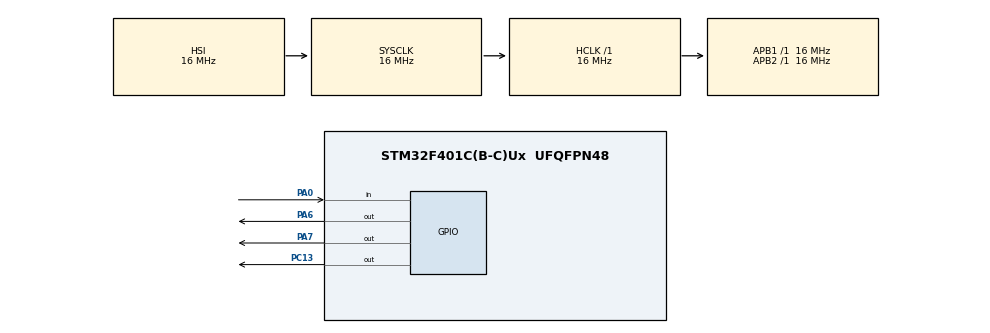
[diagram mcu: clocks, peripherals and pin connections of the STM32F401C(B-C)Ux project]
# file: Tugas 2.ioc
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Mcu.Family=STM32F4
Mcu.Name=STM32F401C(B-C)Ux
Mcu.Package=UFQFPN48
NVIC.PriorityGroup=NVIC_PRIORITYGROUP_4
PA0-WKUP.Signal=GPIO_Input
PA13.Mode=Serial_Wire
PA13.Signal=SYS_JTMS-SWDIO
PA14.Mode=Serial_Wire
PA14.Signal=SYS_JTCK-SWCLK
PA6.Signal=GPIO_Output
PA7.Signal=GPIO_Output
PC13-ANTI_TAMP.Signal=GPIO_Output
ProjectManager.HeapSize=0x200
ProjectManager.StackSize=0x400
ProjectManager.TargetToolchain=STM32CubeIDE
RCC.AHBFreq_Value=16000000
RCC.APB1Freq_Value=16000000
RCC.APB2Freq_Value=16000000
RCC.CortexFreq_Value=16000000
RCC.HSE_VALUE=25000000
RCC.HSI_VALUE=16000000
RCC.LSE_VALUE=32768
RCC.SYSCLKFreq_VALUE=16000000
RCC.VCOOutputFreq_Value=192000000
board=custom

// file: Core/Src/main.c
/* USER CODE BEGIN Header */
/**
  **************************
  * @file           : main.c
  * @brief          : Main program body
  **************************
  * @attention
  *
  * Copyright (c) 2025 STMicroelectronics.
  * All rights reserved.
  *
  * This software is licensed under terms that can be found in the LICENSE file
  * in the root directory of this software component.
  * If no LICENSE file comes with this software, it is provided AS-IS.
  *
  **************************
  */
/* USER CODE END Header */
#include "main.h"

/* USER CODE BEGIN Includes */
volatile uint8_t mode = 4; // Variasi LED (0-3)
volatile uint32_t lastDebounceTimeBtn1 = 0;
volatile uint32_t lastDebounceTimeBtn2 = 0;
const uint32_t debounceDelay = 200; // ms
/* USER CODE END Includes */

/* USER CODE BEGIN PTD */
#define LED_BUILTIN_PIN    GPIO_PIN_13
#define LED_BUILTIN_PORT   GPIOC
#define LED1_PIN           GPIO_PIN_7
#define LED1_PORT          GPIOA
#define LED2_PIN           GPIO_PIN_6
#define LED2_PORT          GPIOA
/* USER CODE END PTD */

/* USER CODE BEGIN PD */
void setLEDsOff(void);
void updateLEDs(uint8_t mode);

/* Callback interrupt tombol dengan debouncing */
void HAL_GPIO_EXTI_Callback(uint16_t GPIO_Pin)
{
    uint32_t currentTime = HAL_GetTick();

    if(GPIO_Pin == GPIO_PIN_0) // Tombol 1: toggle default <-> variasi
    {
        if((currentTime - lastDebounceTimeBtn1) > debounceDelay)
        {
            if(mode == 4)
                mode = 0;
            else
                mode = 4;

            lastDebounceTimeBtn1 = currentTime;
        }
    }
    else if(GPIO_Pin == GPIO_PIN_1) // Tombol 2: loop mode variasi 1-4
    {
        if(((currentTime - lastDebounceTimeBtn2) > debounceDelay ) && (mode != 4))
        {
            mode = (mode + 1) % 3; // 0 -> pola1, 1 -> pola2, 2 -> pola3, 3 -> mati
            lastDebounceTimeBtn2 = currentTime;
        }
    }
}

/* USER CODE END PD */

void SystemClock_Config(void);
static void MX_GPIO_Init(void);

int main(void)
{

  /* MCU Configuration--------------------------------------------------------*/

  /* Reset of all peripherals, Initializes the Flash interface and the Systick. */
  HAL_Init();

  /* Configure the system clock */
  SystemClock_Config();

  /* Initialize all configured peripherals */
  MX_GPIO_Init();

  /* Infinite loop */
  while (1)
  {
	  uint8_t currentMode;
	  __disable_irq();
	  currentMode = mode;
	  __enable_irq();

	  updateLEDs(currentMode);

  }
}

void updateLEDs(uint8_t mode)
{
    switch(mode)
    {

        case 0: // LED PC13 & PB1 kedip bersama 300 ms
            HAL_GPIO_TogglePin(LED_BUILTIN_PORT, LED_BUILTIN_PIN);
            HAL_GPIO_TogglePin(LED1_PORT, LED1_PIN);
            HAL_GPIO_WritePin(LED2_PORT, LED2_PIN, GPIO_PIN_RESET);
            HAL_Delay(300);
            break;

        case 1: // LED PB1 & PB2 nyala bergantian 400 ms
            HAL_GPIO_WritePin(LED_BUILTIN_PORT, LED_BUILTIN_PIN, GPIO_PIN_RESET);
            HAL_GPIO_WritePin(LED1_PORT, LED1_PIN, GPIO_PIN_SET);
            HAL_GPIO_WritePin(LED2_PORT, LED2_PIN, GPIO_PIN_RESET);
            HAL_Delay(400);
            HAL_GPIO_WritePin(LED1_PORT, LED1_PIN, GPIO_PIN_RESET);
            HAL_GPIO_WritePin(LED2_PORT, LED2_PIN, GPIO_PIN_SET);
            HAL_Delay(400);
            break;

        case 2: // Semua LED nyala terus
            HAL_GPIO_WritePin(LED_BUILTIN_PORT, LED_BUILTIN_PIN, GPIO_PIN_SET);
            HAL_GPIO_WritePin(LED1_PORT, LED1_PIN, GPIO_PIN_SET);
            HAL_GPIO_WritePin(LED2_PORT, LED2_PIN, GPIO_PIN_SET);
            HAL_Delay(500);
            break;

        default:
            setLEDsOff();
            HAL_Delay(500);
            break;
    }
}
void SystemClock_Config(void)
{
  RCC_OscInitTypeDef RCC_OscInitStruct = {0};
  RCC_ClkInitTypeDef RCC_ClkInitStruct = {0};

  /** Configure the main internal regulator output voltage
  */
  __HAL_RCC_PWR_CLK_ENABLE();
  __HAL_PWR_VOLTAGESCALING_CONFIG(PWR_REGULATOR_VOLTAGE_SCALE2);

  /** Initializes the RCC Oscillators according to the specified parameters
  * in the RCC_OscInitTypeDef structure.
  */
  RCC_OscInitStruct.OscillatorType = RCC_OSCILLATORTYPE_HSI;
  RCC_OscInitStruct.HSIState = RCC_HSI_ON;
  RCC_OscInitStruct.HSICalibrationValue = RCC_HSICALIBRATION_DEFAULT;
  RCC_OscInitStruct.PLL.PLLState = RCC_PLL_NONE;
  if (HAL_RCC_OscConfig(&RCC_OscInitStruct) != HAL_OK)
  {
    Error_Handler();
  }

  /** Initializes the CPU, AHB and APB buses clocks
  */
  RCC_ClkInitStruct.ClockType = RCC_CLOCKTYPE_HCLK|RCC_CLOCKTYPE_SYSCLK
                              |RCC_CLOCKTYPE_PCLK1|RCC_CLOCKTYPE_PCLK2;
  RCC_ClkInitStruct.SYSCLKSource = RCC_SYSCLKSOURCE_HSI;
  RCC_ClkInitStruct.AHBCLKDivider = RCC_SYSCLK_DIV1;
  RCC_ClkInitStruct.APB1CLKDivider = RCC_HCLK_DIV1;
  RCC_ClkInitStruct.APB2CLKDivider = RCC_HCLK_DIV1;

  if (HAL_RCC_ClockConfig(&RCC_ClkInitStruct, FLASH_LATENCY_0) != HAL_OK)
  {
    Error_Handler();
  }
}

static void MX_GPIO_Init(void)
{
  GPIO_InitTypeDef GPIO_InitStruct = {0};

  /* GPIO Ports Clock Enable */
  __HAL_RCC_GPIOC_CLK_ENABLE();
  __HAL_RCC_GPIOA_CLK_ENABLE();

  /*Configure GPIO pin Output Level */
  HAL_GPIO_WritePin(GPIOC, GPIO_PIN_13, GPIO_PIN_RESET);

  /*Configure GPIO pin Output Level */
  HAL_GPIO_WritePin(GPIOA, GPIO_PIN_6|GPIO_PIN_7, GPIO_PIN_RESET);

  /*Configure GPIO pin : PC13 */
  GPIO_InitStruct.Pin = GPIO_PIN_13;
  GPIO_InitStruct.Mode = GPIO_MODE_OUTPUT_PP;
  GPIO_InitStruct.Pull = GPIO_NOPULL;
  GPIO_InitStruct.Speed = GPIO_SPEED_FREQ_LOW;
  HAL_GPIO_Init(GPIOC, &GPIO_InitStruct);

  /*Configure GPIO pins : PA6 PA7 */
  GPIO_InitStruct.Pin = GPIO_PIN_6|GPIO_PIN_7;
  GPIO_InitStruct.Mode = GPIO_MODE_OUTPUT_PP;
  GPIO_InitStruct.Pull = GPIO_NOPULL;
  GPIO_InitStruct.Speed = GPIO_SPEED_FREQ_LOW;
  HAL_GPIO_Init(GPIOA, &GPIO_InitStruct);

  /*Configure GPIO pin : PA0 */
  GPIO_InitStruct.Pin = GPIO_PIN_0;
  GPIO_InitStruct.Mode = GPIO_MODE_IT_FALLING;  // atau IT_RISING, tergantung tombol
  GPIO_InitStruct.Pull = GPIO_PULLUP;
  HAL_GPIO_Init(GPIOA, &GPIO_InitStruct);

  /*Configure GPIO pin : PA1 */
  GPIO_InitStruct.Pin = GPIO_PIN_1;
  GPIO_InitStruct.Mode = GPIO_MODE_IT_FALLING;  // atau IT_RISING, tergantung tombol
  GPIO_InitStruct.Pull = GPIO_PULLUP;
  HAL_GPIO_Init(GPIOA, &GPIO_InitStruct);

  /*Configure GPIO pin : PA0 */
  HAL_NVIC_SetPriority(EXTI1_IRQn, 2, 0);
  HAL_NVIC_EnableIRQ(EXTI1_IRQn);

  // Enable interrupt EXTI0
  HAL_NVIC_SetPriority(EXTI0_IRQn, 2, 0);
  HAL_NVIC_EnableIRQ(EXTI0_IRQn);

}

/* USER CODE BEGIN 4 */
void EXTI0_IRQHandler(void)
{
  HAL_GPIO_EXTI_IRQHandler(GPIO_PIN_0);
}

void EXTI1_IRQHandler(void)
{
  HAL_GPIO_EXTI_IRQHandler(GPIO_PIN_1);
}

/* USER CODE BEGIN 4 */

void setLEDsOff(void)
{
    HAL_GPIO_WritePin(LED_BUILTIN_PORT, LED_BUILTIN_PIN, GPIO_PIN_RESET);
    HAL_GPIO_WritePin(LED1_PORT, LED1_PIN, GPIO_PIN_RESET);
    HAL_GPIO_WritePin(LED2_PORT, LED2_PIN, GPIO_PIN_RESET);
}

/* USER CODE END 4 */

void Error_Handler(void)
{
  __disable_irq();
  while (1)
  {
  }
}
